# MMC register map
Vendor: Texas Instruments
Peripheral module from a debugger description file (folder DM50x).
Registers are 32-bit, access per field, reset 0x0 unless marked. A register's access mark holds for its fields unless they carry their own. Offsets are as the file gives them; lines under a group give offsets from that group; [hi:lo] are bit positions; {n}, {i} and the like mark numbered series; 'fields as' and 'values as' point back to an identical list; <NAME> marks a mode.

## MMC (part 1 of 2)
0x00 MMCHS_HL_REV ro reset not defined — IP Revision Identifier (X.Y.R) Used by software to track features, bugs, and compatibility
  [31:0] REVISION — IP Revision
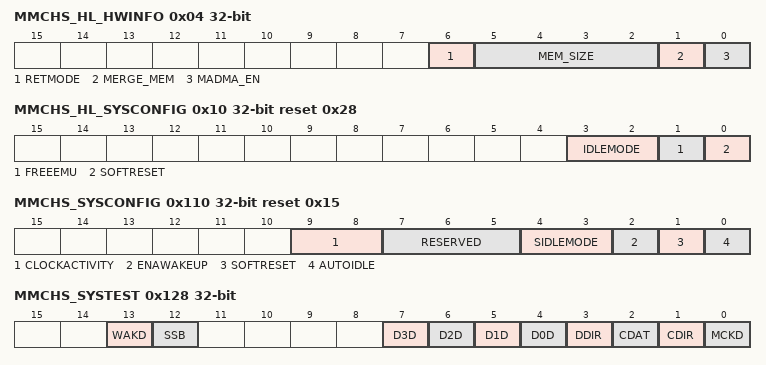
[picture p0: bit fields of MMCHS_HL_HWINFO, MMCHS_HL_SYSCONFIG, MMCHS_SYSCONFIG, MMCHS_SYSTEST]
0x04 MMCHS_HL_HWINFO ro reset not defined — Information about the IP module's hardware configuration.
  [6] RETMODE — Retention Mode generic parameter This bit field indicates whether the retention mode is supported using the pin PIRFFRET.
    1=RetEnabled (Retention mode enabled); 0=RetDisabled (Retention mode disabled)
  [5:2] MEM_SIZE — Memory size for FIFO buffer:
    2=MEM_1024 (Memory of 1024 bytes, max block length is 1024 bytes); 1=MEM_512 (Memory of 512 bytes, max block length is 512 bytes); 8=MEM_4096 (Memory of 4096 bytes, max block length is 2048 bytes); 4=MEM_2048 (Memory of 2048 bytes, max block length is 2048 bytes)
  [1] MERGE_MEM — Memory merged for FIFO buffer: This register defines the configuration of FIFO buffer architecture. If the bit is set STA and DFT shall support clock multiplexing and balancing.
    1=SingleMemBuffer (A single memory is used with multiplexed addresses, data and clocks.); 0=TwoMemBuffer (2 memories instantiated, one per data transfer direction.)
  [0] MADMA_EN — Master DMA enabled generic parameter: This register defines the configuration of the controller to know if it supports the master DMA management called ADMA.
    1=SupportADMA (Controller supports ADMA); 0=No Master DMA (ADMA) management supported
0x10 MMCHS_HL_SYSCONFIG reset 0x28 — Clock Management Configuration Register
  [3:2] IDLEMODE rw — Configuration of the local target state management mode. By definition, target can handle read/write transaction as long as it is out of IDLE state.
    0=Force-idle mode: local target's idle state follows (acknowledges) the system's IDLE requests unconditionally, i.e. regardless of the IP module's internal requirements.Backup mode, for debug only.; 1=No-idle mode: local target never enters idle state.Backup mode, for debug only; 3=Smart-idle wakeup-capable mode: local target's idle state eventually follows (acknowledges) the system's IDLE requests, depending on the IP module's internal requirements.IP module may generate (IRQ- or DMA-request-related) wakeup events when in idle state.Mode is only relevant if the appropriate IP module 'swakeup' output(s) is (are) implemented; 2=Smart-idle mode: local target's idle state eventually follows (acknowledges) the system's IDLE requests, depending on the IP module's internal requirements.IP module shall not generate (IRQ- or DMA-request-related) wakeup events
  [1] FREEEMU rw — Sensitivity to emulation (debug) suspend input signal. Functionality NOT implemented in MMCHS.
    0=EmuEn (IP module is sensitive to emulation suspend); 1=EmuDis (IP module is not sensitive to emulation suspend)
  [0] SOFTRESET rw — Software reset. (Optional)
    0=NoAction; 1=SoftReset (Initiate software reset); 1=ResetOnGoing (Reset (software or other) ongoing); 0=Reset done, no pending action
0x110 MMCHS_SYSCONFIG reset 0x15 — System Configuration Register This register allows controlling various parameters of the Interconnect interface.
  [9:8] CLOCKACTIVITY rw — Clocks activity during wake up mode period. Bit8: Interface clock Bit9: Functional clock
    0=None (Interface and Functional clock may be switched off.); 1=OCP (Interface clock is maintained. Functional clock may be switched-off.); 3=Both (Interface and Functional clocks are maintained.); 2=Functional clock is maintained. Interface clock may be switched-off.
  [7:5] RESERVED ro — This bit is initialized to zero, and writes to it are ignored. Reads return 0.
  [4:3] SIDLEMODE rw — Power management
    0=Force (If an IDLE request is detected, the SDIO controller acknowledges it unconditionally and goes in Inactive mode. Interrupt and DMA requests are unconditionally de-asserted.); 1=NoIdle (If an IDLE request is detected, the request is ignored and the module keeps on behaving normally.); 3=SmartWake (Smart-idle wakeup-capable mode: local target's idle state eventually follows (acknowledges) the system's IDLE requests, depending on the IP module's internal requirements.IP module may generate (IRQ- or DMA-request-related) wakeup events when in idle state.Mode is only relevant if the appropriate IP module 'swakeup' output(s) is (are) implemented.); 2=Smart-idle mode: local target's idle state eventually follows (acknowledges) the system's IDLE requests, depending on the IP module's internal requirements.IP module shall not generate (IRQ- or DMA-request-related) wakeup events
  [2] ENAWAKEUP rw — Wakeup feature control
    0=Disabled (Wakeup capability is disabled); 1=Enable (Wakeup capability is enabled)
  [1] SOFTRESET rw — Software reset. The bit is automatically reset by the hardware. During reset, it always returns 0.
    0=St_un_w (No effect.); 1=St_rst_w (Trigger a module reset.); 1=OnReset_r (The module is reset.); 0=NoReset_r (Normal mode)
  [0] AUTOIDLE rw — Internal Clock gating strategy
    0=Off (Clocks are free-running); 1=On (Automatic clock gating strategy is applied, based on the Interconnect and SDIO interface activity)
0x114 MMCHS_SYSSTATUS ro — System Status Register This register provides status information about the module excluding the interrupt status information
  [0] RESETDONE — Internal Reset Monitoring Note: the debounce clock , the system clock (Interface) and the functional clock shall be provided to the SDIO host controller to allow the internal reset monitoring.
    1=Done (Reset completed.); 0=OnGoing (Internal module reset is on-going)
0x124 MMCHS_CSRE rw — Card Status Response Error This register enables the host controller to detect card status errors of response type R1, R1b for all cards and of R5, R5b and R6 response for cards types SD or SDIO. When a bit [i] is set to 1, if the corresponding bit at the same position in the response MMCHS_RSP0[i] is set to 1, the host controller indicates a card error ([CERR]) interrupt status to avoid the host driver reading the response register (). Note: No automatic card error detection for autoCMD12 is implemented; the host system has to check autoCMD12 response register () for possible card errors.
  [31:0] CSRE — Card status response error
0x128 MMCHS_SYSTEST — System Test Register This register is used to control the signals that connect to I/O pins when the module is configured in system test (SYSTEST) mode for boundary connectivity verification. Note: In SYSTEST mode, a write into register will not start a transfer. The buffer behaves as a stack accessible only by the local host (push and pop operations). In this mode, the Transfer Block Size ([BLEN]) and the Blocks count for current transfer ([NBLK]) are needed to generate a Buffer write ready interrupt ([BWR]) or a Buffer read ready interrupt ([BRR]) and DMA requests if enabled.
  [13] WAKD rw — Wake request output signal data value
    0=DrivenLow_w (The pin SWAKEUP is driven low.); 1=DrivenHIgh_w (The pin SWAKEUP is driven high.); 1=One_r (No action. Returns 1.); 0=Zero_r (No action. Returns 0.)
  [12] SSB rw — Set status bit This bit must be cleared prior attempting to clear a status bit of the interrupt status register (MMCHS_STAT).
    0=Clear_w (Clear this SSB bitfield. Writing 0 does not clear already set status bits;); 1=SetThemAll_w (Force to 1 all status bits of the interrupt status register () only if the corresponding bitfield in the Interrupt signal enable register () is set.); 1=One_r (No action. Returns 1.); 0=Zero_r (No action. Returns 0.)
  [7] D3D rw — DAT3 input/output signal data value
    0=DriveLow_w (If SYSTEST[DDIR] = 0 (output mode direction), the DAT3 line is driven low. If SYSTEST[DDIR] = 1 (input mode direction), no effect.); 1=DriveHigh_w (If SYSTEST[DDIR] = 0 (output mode direction), the DAT3 line is driven high. If SYSTEST[DDIR] = 1 (input mode direction), no effect.); 1=One_r (If SYSTEST[DDIR] = 1 (input mode direction), returns the value on the DAT3 line (high) If SYSTEST[DDIR] = 0 (output mode direction), returns 1); 0=Zero_r (If SYSTEST[DDIR] = 1 (input mode direction), returns the value on the DAT3 line (low). If SYSTEST[DDIR] = 0 (output mode direction), returns 0)
  [6] D2D rw — DAT2 input/output signal data value
    0=DriveLow_w (If SYSTEST[DDIR] = 0 (output mode direction), the DAT2 line is driven low. If SYSTEST[DDIR] = 1 (input mode direction), no effect.); 1=DriveHigh_w (If SYSTEST[DDIR] = 0 (output mode direction), the DAT2 line is driven high. If SYSTEST[DDIR] = 1 (input mode direction), no effect.); 1=One_r (If SYSTEST[DDIR] = 1 (input mode direction), returns the value on the DAT2 line (high) If SYSTEST[DDIR] = 0 (output mode direction), returns 1); 0=Zero_r (If SYSTEST[DDIR] = 1 (input mode direction), returns the value on the DAT2 line (low). If SYSTEST[DDIR] = 0 (output mode direction), returns 0)
  [5] D1D rw — DAT1 input/output signal data value
    0=DriveLow_w (If SYSTEST[DDIR] = 0 (output mode direction), the DAT1 line is driven low. If SYSTEST[DDIR] = 1 (input mode direction), no effect.); 1=DriveHigh_w (If SYSTEST[DDIR] = 0 (output mode direction), the DAT1 line is driven high. If SYSTEST[DDIR] = 1 (input mode direction), no effect.); 1=One_r (If SYSTEST[DDIR] = 1 (input mode direction), returns the value on the DAT1 line (high) If SYSTEST[DDIR] = 0 (output mode direction), returns 1); 0=Zero_r (If SYSTEST[DDIR] = 1 (input mode direction), returns the value on the DAT1 line (low). If SYSTEST[DDIR] = 0 (output mode direction), returns 0)
  [4] D0D rw — DAT0 input/output signal data value
    0=Zero_w (If SYSTEST[DDIR] = 0 (output mode direction), the DAT0 line is driven low. If SYSTEST[DDIR] = 1 (input mode direction), no effect.); 1=DriveHigh_w (If SYSTEST[DDIR] = 0 (output mode direction), the DAT0 line is driven high. If SYSTEST[DDIR] = 1 (input mode direction), no effect.); 1=One_r (If SYSTEST[DDIR] = 1 (input mode direction), returns the value on the DAT0 line (high) If SYSTEST[DDIR] = 0 (output mode direction), returns 1); 0=Zero_r (If SYSTEST[DDIR] = 1 (input mode direction), returns the value on the DAT0 line (low). If SYSTEST[DDIR] = 0 (output mode direction), returns 0)
  [3] DDIR rw — Control of the DAT[7:0] pins direction.
    0=Out_w (The DAT lines are outputs (host to card)); 1=In_w (The DAT lines are inputs (card to host)); 1=One_r (No action. Returns 1.); 0=Zero_r (No action. Returns 0.)
  [2] CDAT rw — CMD input/output signal data value
    0=DriveLow_w (If SYSTEST[CDIR] = 0 (output mode direction), the CMD line is driven low. If SYSTEST[CDIR] = 1 (input mode direction), no effect.); 1=DriveHigh_w (If SYSTEST[CDIR] = 0 (output mode direction), the CMD line is driven high. If SYSTEST[CDIR] = 1 (input mode direction), no effect.); 1=One_r (If SYSTEST[CDIR] = 1 (input mode direction), returns the value on the CMD line (high) If SYSTEST[CDIR] = 0 (output mode direction), returns 1); 0=Zero_r (If SYSTEST[CDIR] = 1 (input mode direction), returns the value on the CMD line (low). If SYSTEST[CDIR] = 0 (output mode direction), returns 0)
  [1] CDIR rw — Control of the CMD pin direction.
    0=Out_w (The CMD line is an output (host to card)); 1=In_w (The CMD line is an input (card to host)); 1=One_r (No action. Returns 1.); 0=Zero_r (No action. Returns 0.)
  [0] MCKD rw — SDIO clock output signal data value
    0=DrivenLow_w (The output clock is driven low.); 1=DrivenHigh_w (The output clock is driven high.); 1=One_r (No action. Returns 1.); 0=Zero_r (No action. Returns 0.)
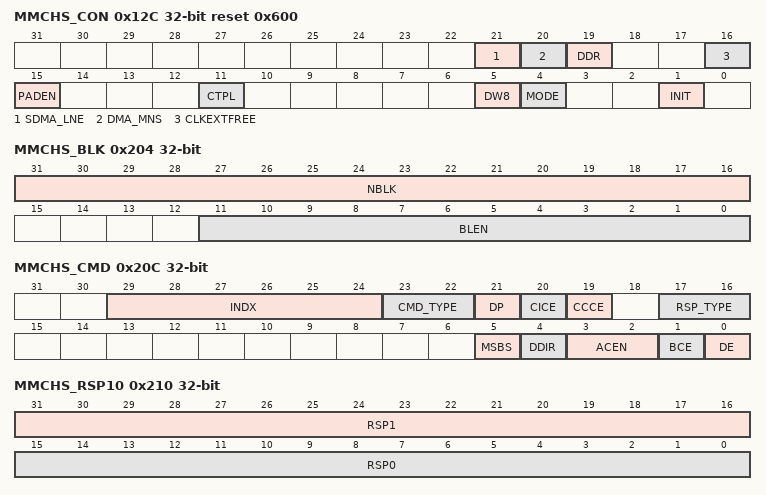
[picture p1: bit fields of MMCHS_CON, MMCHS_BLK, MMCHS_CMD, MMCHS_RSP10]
0x12C MMCHS_CON access not given reset 0x600 — Configuration Register This register is used: - to select the functional mode or the SYSTEST mode for any card. - to send an initialization sequence to any card. - to enable the detection on DAT[1] of a card interrupt for SDIO cards only.
  [21] SDMA_LNE rw — Slave DMA Level/Edge Request: The waveform of the DMA request can be configured either edge sensitive with early de-assertion on first access to MMCHS_DATA register or late de-assertion, request remains active until last allowed data written into MMCHS_DATA.
    0=EarlyDeAssert (Slave DMA edge sensitive, Early DMA de-assertion); 1=LateDeAssert (Slave DMA level sensitive, Late DMA de-assertion)
  [20] DMA_MNS rw — DMA Master or Slave selection: When this bit is set and the controller is configured to use the DMA, Interconnect master interface is used to get datas from system using ADMA2 procedure (direct access to the memory).This option is only available if generic parameter MADMA_EN is asserted to '1'.
    0=MasterDMADis (The controller is slave on data transfers with system.); 1=MasterDMAEn (The controller is master on data exchange with system, controller must be configured as using DMA.NOTE: The SDIO Controller does NOT support Master DMA operations. This bit must be kept to value of 0x0.)
  [19] DDR rw — Dual Data Rate mode: When this register is set, the controller uses both clock edge to emit or receive data. Odd bytes are transmitted on falling edges and even bytes are transmitted on rise edges. It only applies on Data bytes and CRC, Start, end bits and CRC status are kept full cycle. This bit field is only meaningful and active for even clock divider ratio of MMCHS_SYSCTL[CLKD], it is insensitive to MMCHS_HCTL[HSPE] setting.
    0=NormalMode (Standard mode : data are transmitted on a single edge depending on MMCHS_HCTRL[HSPE].); 1=DDRMode (Data Bytes and CRC are transmitted on both edge.NOTE: The SDIO Controller does NOT support DDR mode. This bit must be kept to value of 0x0.)
  [16] CLKEXTFREE rw — External clock free running: This register is used to maintain card clock out of transfer transaction to enable slave module for example to generate a synchronous interrupt on DAT[1]. The Clock will be maintain only if MMCHS_SYSCTL[CEN] is set.
    0=Autogating (External card clock is cut off outside active transaction period.); 1=FreeRunning (External card clock is maintain even out of active transaction period only if[CEN] is set.)
  [15] PADEN rw — Control Power for SDIO Lines: This register is only useful when SDIO PADs contain power saving mechanism to minimize its leakage power. It works as a GPIO that directly control the ACTIVE pin of PADs. Excepted for DAT[1], the signal is also combine outside the module with the dedicated power control MMCHS_CON[CTPL] bit.
    0=Disable (ADPIDLE module pin is not forced, it is automatically generated by the SDIO controller FSMs.); 1=Enable (ADPIDLE module pin is forced to active state.)
  [11] CTPL rw — Control Power for DAT[1] line SD cards: By default, this bit is set to 0 and the host controller automatically disables all the input buffers outside of a transaction to minimize the leakage current. SDIO cards: When this bit is set to 1, the host controller automatically disables all the input buffers except the buffer of DAT[1] outside of a transaction in order to detect asynchronous card interrupt on DAT[1] line and minimize the leakage current of the buffers.
    0=SD (Disable all the input buffers outside of a transaction.); 1=SDIO (Disable all the input buffers except the buffer of DAT[1] outside of a transaction.)
  [5] DW8 rw — 8-bit mode MMC select
    0=1_4BitMode (1-bit or 4-bit Data width (DAT[0] used, SD cards)); 1=8BitMode (8-bit Data width.NOTE: Not supported on this device.)
  [4] MODE rw — Mode select This bit select between Functional mode and SYSTEST mode.
    0=FUNC (Functional mode. Transfers to SD/SDIO cards follow the card protocol. SDIO clock is enabled. SD transfers are operated under the control of the CMD register.); 1=SYSTEST (SYSTEST mode The signal pins are configured as general-purpose input/output and the 1024-byte buffer is configured as a stack memory accessible only by the local host or system DMA. The pins retain their default type (input, output or in-out). SYSTEST mode is operated under the control of the SYSTEST register.)
  [1] INIT rw — Send initialization stream All cards. When this bit is set to 1, and the card is idle, an initialization sequence is sent to the card. An initialization sequence consists of setting the CMD line to 1 during 80 clock cycles. The initialisation sequence is mandatory - but it is not required to do it through this bit - this bit makes it easier. Clock divider (MMCHS_SYSCTL[CLKD]) should be set to ensure that 80 clock periods are greater than 1ms. (section 6.4 in the SD card specification). Note: in this mode, there is no command sent to the card and no response is expected
    0=NoInit (The host does not send an initialization sequence.); 1=InitStream (The host sends an initialization sequence.)
0x130 MMCHS_PWCNT — Power Counter Register This register is used to program a counter to delay command transfers after activating the PAD power, this value depends on PAD characteristics and voltage.
  [15:0] PWRCNT rw — Power counter register. This register is used to introduce a delay between the PAD ACTIVE pin assertion and the command issued.
    0xFFFF=65535cycles (TCF x 65535 delay (card clock period)); 0=nodelay (No additional delay added); 1=1cycles (TCF delay (card clock period)); 0xFFFE=65534cycles (TCF x 65534 delay (card clock period)); 2=2cycles (TCF x 2 delay (card clock period))
0x200 MMCHS_SDMASA rw — This register contains the physical system memory address used for DMA transfers.
  [31:0] SDMA_ARG2 — This register contains the system memory address for a DMA transfer. When the Host Controller stops the DMA transfer, this register shall point to the system address of the next contiguous data position. It can be accessed only if no transaction is executing (i.e., after a transaction has stopped). Read operations during transfers may return an invalid value. The Host Driver shall initialize this register before starting a DMA transaction. After DMA has stopped, the next system address of the next contiguous data position can be read from this register. The DMA transfer waits at the every boundary specified by the Host DMA Buffer Boundary in the Block Size register. The Host Controller generates DMA Interrupt to request the Host Driver to update this register. The Host Driver sets the next system address of the next data position to this register. When the most upper byte of this register (003h) is written, the Host Controller restarts the DMA transfer. When restarting DMA by the Resume command or by setting Continue Request in the Block Gap Control register, the Host Controller shall start at the next contiguous address stored here in the DMA System Address register.
0x204 MMCHS_BLK — Transfer Length Configuration Register [BLEN] is the block size register. [NBLK] is the block count register. This register shall be used for any card.
  [31:16] NBLK rw — Blocks count for current transfer This register is enabled when Block count Enable (MMCHS_CMD[BCE]) is set to 1 and is valid only for multiple block transfers. Setting the block count to 0 results no data blocks being transferred. Note: The host controller decrements the block count after each block transfer and stops when the count reaches zero. This register can be accessed only if no transaction is executing (i.e, after a transaction has stopped). Read operations during transfers may return an invalid value and write operation will be ignored. In suspend context, the number of blocks yet to be transferred can be determined by reading this register. When restoring transfer context prior to issuing a Resume command, The local host shall restore the previously saved block count.
    0xFFFF=65535blks (65535 blocks); 0=Stpcnt (Stop count); 1=1blk (1 block); 2=2blks (2 blocks)
  [11:0] BLEN rw — Transfer Block Size. This register specifies the block size for block data transfers. Read operations during transfers may return an invalid value, and write operations are ignored. When a CMD12 command is issued to stop the transfer, a read of the BLEN field after transfer completion (MMCHS_STAT[TC] set to 1) will not return the true byte number of data length while the stop occurs but the value written in this register before transfer is launched.
    1=1bytelen (1 byte block length); 0x7FF=2047byteslen (2047 bytes block length); 0=Notransfer (No data transfer); 0x1FF=511byteslen (511 bytes block length); 0x800=2048byteslen (2048 bytes block length); 2=2byteslen (2 bytes block length); 3=3byteslen (3 bytes block length); 0x200=512byteslen (512 bytes block length)
0x208 MMCHS_ARG rw — Command Argument Register This register contains command argument specified as bit 39-8 of Command-Format These registers must be initialized prior to sending the command itself to the card (write action into the register register). Only exception is for a command index specifying stuff bits in arguments, making a write unnecessary.
  [31:0] ARG — Command argument bits [31:0]
0x20C MMCHS_CMD — Command and Transfer Mode Register [31:16] = the command register [15:0] = the transfer mode. This register configures the data and command transfers. A write into the most significant byte send the command. A write into [15:0] registers during data transfer has no effect. This register shall be used for any card. Note: In SYSTEST mode, a write into register will not start a transfer.
  [29:24] INDX rw — Command indexBinary encoded value from 0 to 63 specifying the command number send to card .
    {v}=CMD{v} (CMD{v} or ACMD{v}) (v=0..63)
  [23:22] CMD_TYPE rw — Command typeThis register specifies three types of special command: Suspend, Resume and Abort. . These bits shall be set to 00b for all other commands. .
    0=Normal (Others Commands); 1=Suspend (CMD52 for writing 'Bus Suspend' in CCCR); 3=Abort command CMD12, CMD52 for writing ' I/O Abort' in CCCR; 2=Resume (CMD52 for writing 'Function Select' in CCCR)
  [21] DP rw — Data present selectThis register indicates that data is present and DAT line shall be used. . It must be set to 0 in the following conditions: . - command using only CMD line . - command with no data transfer but using busy signal on DAT[0] . - Resume command .
    0=NoData (Command with no data transfer); 1=Data (Command with data transfer)
  [20] CICE rw — Command Index check enableThis bit must be set to 1 to enable index check on command response to compare the index field in the response against the index of the command. . If the index is not the same in the response as in the command, it is reported as a command index error ([CIE] set to1). . Note:The register CICE cannot be configured for an Auto CMD12, then index check is automatically checked when this command is issued. .
    0=Nocheck (Index check disable); 1=Check (Index check enable)
  [19] CCCE rw — Command CRC check enableThis bit must be set to 1 to enable CRC7 check on command response to protect the response against transmission errors on the bus. . If an error is detected, it is reported as a command CRC error ([CCRC] set to 1). . Note: The register CCCE cannot be configured for an Auto CMD12, and then CRC check is automatically checked when this command is issued. .
    0=NoCheck (CRC7 check disable); 1=Check (CRC7 check enable)
  [17:16] RSP_TYPE rw — Response typeThis bits defines the response type of the command .
    0=Norsp (No response); 1=Lght36 (Response Length 136 bits); 3=Lght48b (Response Length 48 bits with busy after response); 2=Lght48 (Response Length 48 bits)
  [5] MSBS rw — Multi/Single block selectThis bit must be set to 1 for data transfer in case of multi block command. . For any others command this bit shall be set to 0. . If this bit is 0, it is not necessary to set the register[NBLK]. enum=sgleblk . When Block Count is disabled ([BCE] is set to 0) in Multiple block transfers ([MSBS] is set to 1), the module can perform infinite transfer. enum=multiblk .
    0=Single_block; 1=multiblk (Multi block.)
  [4] DDIR rw — Data transfer Direction SelectThis bit defines either data transfer will be a read or a write. .
    0=Write (Data Write (host to card)); 1=Read (Data Read (card to host))
  [3:2] ACEN rw — Auto CMD Enable - SD card only.This field determines use of auto command functions. . There are two methods to stop Multiple-block read and write operation . Auto CMD12 Enable When this field is set to 01b, the Host Controller issues CMD12 automatically when last block transfer is completed. Auto CMD12 error is indicated to the Auto CMD Error Status register ( .
    0=Disable (Auto Command Disabled); 1=EnableCMD12 (Auto CMD12 enable or CCS detection enabled.)
  [1] BCE rw — Block Count EnableMultiple block transfers only. . This bit is used to enable the block count register ([NBLK]). . When Block Count is disabled ([BCE] is set to 0) in Multiple block transfers ([MSBS] is set to 1), the module can perform infinite transfer. .
    0=Disable (Block count disabled for infinite transfer.); 1=Enable (Block count enabled for multiple block transfer with known number of blocks)
  [0] DE rw — DMA EnableThis bit is used to enable DMA mode for host data access. .
    0=Disable (DMA mode disable); 1=Enable (DMA mode enable)
0x210 MMCHS_RSP10 ro — Command Response[31:0] Register (bits [31:0] of the internal RSP register). This 32-bit register holds bits positions [31:0] of command response type R1/R1b/R2/R3/R4/R5/R5b/R6/R7
  [31:16] RSP1 — Command Response [31:16]
  [15:0] RSP0 — Command Response [15:0]
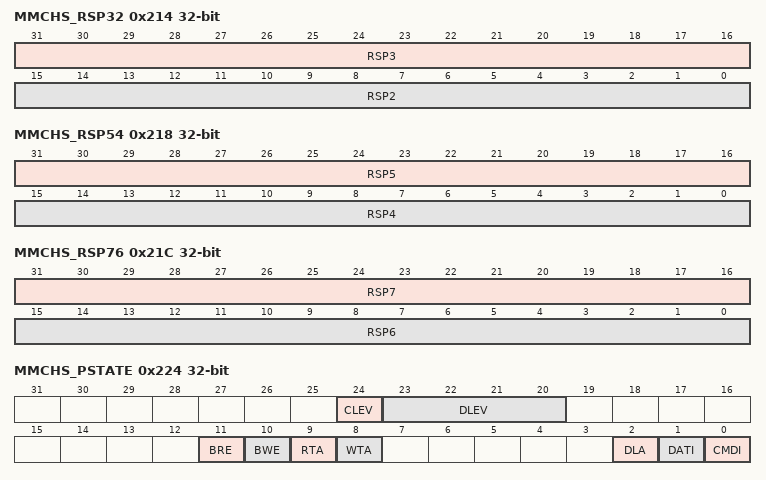
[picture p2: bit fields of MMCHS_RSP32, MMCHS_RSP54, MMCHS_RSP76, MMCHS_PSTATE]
0x214 MMCHS_RSP32 ro — Command Response[63:32] Register (bits [63:32] of the internal RSP register) This 32-bit register holds bits positions [63:32] of command response type R2
  [31:16] RSP3 — Command Response [63:48]
  [15:0] RSP2 — Command Response [47:32]
0x218 MMCHS_RSP54 ro — Command Response[95:64] Register (bits [95:64] of the internal RSP register) This 32-bit register holds bits positions [95:64] of command response type R2
  [31:16] RSP5 — Command Response [95:80]
  [15:0] RSP4 — Command Response [79:64]
0x21C MMCHS_RSP76 ro — Command Response[127:96] Register (bits [127:96] of the internal RSP register) This 32-bit register holds bits positions [127:96] of command response type R1/R1b(Auto CMD12)/R2
  [31:16] RSP7 — Command Response [127:112]
  [15:0] RSP6 — Command Response [111:96]
0x220 MMCHS_DATA rw — Data Register This register is the 32-bit entry point of the buffer for read or write data transfers. The buffer size is 32bits x256(1024 bytes). Bytes within a word are stored and read in little endian format. This buffer can be used as two 512 byte buffers to transfer data efficiently without reducing the throughput. Sequential and contiguous access is necessary to increment the pointer correctly. Random or skipped access is not allowed. In little endian, if the local host accesses this register byte-wise or 16bit-wise, the least significant byte (bits [7:0]) must always be written/read first. The update of the buffer address is done on the most significant byte write for full 32-bit DATA register or on the most significant byte of the last word of block transfer. Example 1: Byte or 16-bit access Mbyteen[3:0]=0001 (1-byte) => Mbyteen[3:0]=0010 (1-byte) => Mbyteen[3:0]=1100 (2-bytes) OK Mbyteen[3:0]=0001 (1-byte) => Mbyteen[3:0]=0010 (1-byte) => Mbyteen[3:0]=0100 (1-byte) OK Mbyteen[3:0]=0001 (1-byte) => Mbyteen[3:0]=0010 (1-byte) => Mbyteen[3:0]=1000 (1-byte) Bad
  [31:0] DATA — Data Register [31:0] In functional mode (MMCHS_CON[MODE] set to the default value 0) , A read access to this register is allowed only when the buffer read enable status is set to 1 (MMCHS_PSTATE[BRE]), otherwise a bad access (MMCHS_STAT[BADA]) is signaled. A write access to this register is allowed only when the buffer write enable status is set to 1(MMCHS_STATE[BWE]), otherwise a bad access (MMCHS_STAT[BADA]) is signaled and the data is not written.
0x224 MMCHS_PSTATE ro (reset mask 0xFE000FFF) — Present State Register The Host can get status of the Host Controller from this 32-bit read only register.
  [24] CLEV — CMD line signal level This status is used to check the CMD line level to recover from errors, and for debugging. The value of this register after reset depends on the CMD line level at that time.
    1=One (The CMD line level is 1.); 0=Zero (The CMD line level is 0.)
  [23:20] DLEV — DAT[3:0] line signal level DAT[3] =&gt; bit 23 DAT[2] =&gt; bit 22 DAT[1] =&gt; bit 21 DAT[0] =&gt; bit 20 This status is used to check DAT line level to recover from errors, and for debugging. This is especially useful in detecting the busy signal level from DAT[0]. The value of these registers after reset depends on the DAT lines level at that time.
  [11] BRE — Buffer read enable This bit is used for non-DMA read transfers. It indicates that a complete block specified by MMCHS_BLK[BLEN] has been written in the buffer and is ready to be read. It is set to 0 when the entire block is read from the buffer. It is set to 1 when a block data is ready in the buffer and generates the Buffer read ready status of interrupt (MMCHS_STAT[BRR]).
    1=RdEnable (Read BLEN bytes enable. Readable data exists in the buffer.); 0=RdDisable (Read BLEN bytes disable)
  [10] BWE — Buffer Write enable This status is used for non-DMA write transfers. It indicates if space is available for write data.
    1=WrEnable (There is enough space in the buffer to write BLEN bytes of data.); 0=WrDisable (There is no room left in the buffer to write BLEN bytes of data.)
  [9] RTA — Read transfer active This status is used for detecting completion of a read transfer. It is set to 1 after the end bit of read command or by activating a continue request (MMCHS_HCTL[CR]) following a stop at block gap request. This bit is set to 0 when all data have been read by the local host after last block or after a stop at block gap request.
    1=Transfer (read data transfer on going.); 0=NoTransfer (No valid data on the DAT lines.)
  [8] WTA — Write transfer active This status indicates a write transfer active. It is set to 1 after the end bit of write command or by activating a continue request (MMCHS_HCTL[CR]) following a stop at block gap request. This bit is set to 0 when CRC status has been received after last block or after a stop at block gap request.
    1=Transfer (Write data transfer on going.); 0=NoTransfer (No valid data on the DAT lines.)
  [2] DLA — DAT line active This status bit indicates whether one of the DAT line is in use. In the case of read transactions (card to host): This bit is set to 1 after the end bit of read command or by activating continue request MMCHS_HCTL[CR]. This bit is set to 0 when the host controller received the end bit of the last data block or at the beginning of the read wait mode. In the case of write transactions (host to card): This bit is set to 1 after the end bit of write command or by activating continue request MMCHS_HCTL[CR]. This bit is set to 0 on the end of busy event for the last block; host controller must wait 8 clock cycles with line not busy to really consider not 'busy state' or after the busy block as a result of a stop at gap request.
    1=one (DAT Line active); 0=zero (DAT Line inactive)
  [1] DATI — Command inhibit(DAT) This status bit is generated if either DAT line is active (MMCHS_PSTATE[DLA]) or Read transfer is active (MMCHS_PSTATE[RTA]) or when a command with busy is issued. This bit prevents the local host to issue a command. A change of this bit from 1 to 0 generates a transfer complete interrupt (MMCHS_STAT[TC]).
    1=Cmddis (Issuing of command using DAT lines is not allowed); 0=Cmden (Issuing of command using the DAT lines is allowed)
  [0] CMDI — Command inhibit(CMD) This status bit indicates that the CMD line is in use. This bit is set to 0 when the most significant byte is written into the command register. This bit is not set when Auto CMD12 is transmitted. This bit is set to 0 in either the following cases: - After the end bit of the command response, excepted if there is a command conflict error (MMCHS_STAT[CCRC] or MMCHS_STAT[CEB] set to 1) or a Auto CMD12 is not executed (MMCHS_AC12[ACNE]). - After the end bit of the command without response (MMCHS_CMD[RSP_TYPE] set to '00') In case of a command data error is detected (MMCHS_STAT[CTO] set to 1), this register is not automatically cleared.
    1=Cmddis (Issuing of command using CMD line is not allowed); 0=Cmden (Issuing of command using CMD line is allowed)
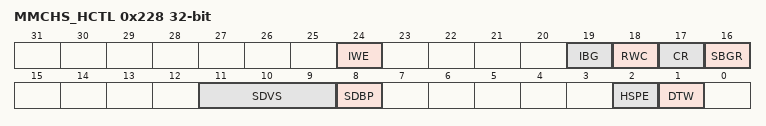
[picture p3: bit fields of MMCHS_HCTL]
0x228 MMCHS_HCTL — Host Control Register This register defines the host controls to set power, wakeup and transfer parameters. [24] = Wakeup control [23:16] = Block gap control [15:8] = Power control [7:0] = Host control
  [24] IWE rw — Wakeup event enable on SD card interrupt This bit enables wakeup events for card interrupt assertion. Wakeup is generated if the wakeup feature is enabled (MMCHS_SYSCONFIG[ENAWAKEUP]).
    0=Disable wakeup on card interrupt; 1=Enable wakeup on card interrupt
  [19] IBG rw — Interrupt block at gap This bit is valid only in 4-bit mode of SDIO card to enable interrupt detection in the interrupt cycle at block gap for a multiple block transfer. For SD cards this bit should be set to 0.
    0=Itdiable (Disable interrupt detection at the block gap in 4-bit mode); 1=Itenable (Enable interrupt detection at the block gap in 4-bit mode)
  [18] RWC rw — Read wait control The read wait function is optional only for SDIO cards. If the card supports read wait, this bit must be enabled, then requesting a stop at block gap (MMCHS_HCTL[SBGR]) generates a read wait period after the current end of block. Be careful, if read wait is not supported it may cause a conflict on DAT line.
    0=NoRW (Disable Read Wait Control. Suspend/Resume cannot be supported.); 1=RW (Enable Read Wait Control)
  [17] CR rw — Continue request This bit is used to restart a transaction that was stopped by requesting a stop at block gap (MMCHS_HCTL[SBGR]). Set this bit to 1 restarts the transfer. The bit is automatically set to 0 by the host controller when transfer has restarted i.e DAT line is active (MMCHS_PSTATE[DLA]) or transferring data (MMCHS_PSTATE[WTA]). The Stop at block gap request must be disabled (MMCHS_HCTL[SBGR]=0) before setting this bit.
    0=None (No affect); 1=Restart (transfer restart)
  [16] SBGR rw — Stop at block gap request This bit is used to stop executing a transaction at the next block gap. The transfer can restart with a continue request (MMCHS_HCTL[CR]) or during a suspend/resume sequence. In case of read transfer, the card must support read wait control. In case of write transfer, the host driver shall set this bit after all block data written. Until the transfer completion (MMCHS_STAT[TC] set to 1), the host driver shall leave this bit set to 1. If this bit is set, the local host shall not write to the data register (MMCHS_DATA).
    0=Transfer mode; 1=Stpblk (Stop at block gap)
  [11:9] SDVS rw — SD bus voltage select All cards. The host driver should set to these bits to select the voltage level for the card according to the voltage supported by the system (MMCHS_CAPA[VS18,VS30,VS33]) before starting a transfer.
    6=3V0 (3.0V (Typical)); 7=3V3 (3.3V (Typical)); 5=1V8 (1.8V (Typical))
  [8] SDBP rw — SD bus power Before setting this bit, the host driver shall select the SD bus voltage (MMCHS_HCTL[SDVS]). If the host controller detects the No card state, this bit is automatically set to 0. If the module is power off, a write in the command register (MMCHS_CMD) will not start the transfer. A write to this bit has no effect if the selected SD bus voltage MMCHS_HCTL[SDVS] is not supported according to capability register (MMCHS_CAPA[VS*]).
    0=Pwroff (Power off); 1=Pwron (Power on)
  [2] HSPE rw — Before setting this bit, the Host Driver shall check theMMCHS_CAPA[21] HSS. . If this bit is set to 1, the Host Controller outputs CMD line and DAT lines at the rising edge of the SD Clock.This bit shall not be set when dual data rate mode is activated in MMCHS_CON[DDR].
    0=NormalSpeed (Тhe Host Controller outputs CMD line and DAT lines at the falling edge of the SD Clock); 1=HighSpeed (Тhe Host Controller outputs CMD line and DAT lines at the rising edge of the SD Clock NOTE: Do not set this bit to 0x1 as timings cannot be met at high speeds. It is recommended to not modify it and keep its default value of 0x0.)
  [1] DTW rw — Data transfer width For SD/SDIO cards, this bit must be set following a valid SET_BUS_WIDTH command (ACMD6) with the value written in bit 1 of the argument. Prior to this command, the SD card configuration register (SCR) must be verified for the supported bus width by the SD card.
    0=1_BitMode (1-bit Data width (DAT[0] used)); 1=4_BitMode (4-bit Data width (DAT[3:0] used))
